# nrf54lilium_network register map
Vendor: Nordic Semiconductor; Series: nrf54; File version: 1
CPU: CM33 r0p4, little endian, MPU, no FPU, 3 interrupt priority bits, 30 interrupts
Registers are 32-bit, read-write, reset 0x0 unless marked. A register's access mark holds for its fields unless they carry their own. Offsets are from the block's base; [hi:lo] are bit positions; {n}, {i} and the like mark numbered series; 'fields as' and 'values as' point back to an identical list.

## RADIO (part 3 of 3) — 2.4 GHz radio 2.4 GHz radio
Base 0x41008000
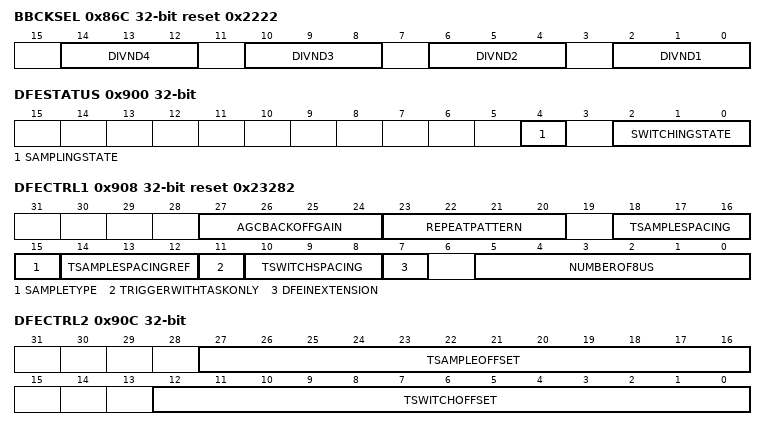
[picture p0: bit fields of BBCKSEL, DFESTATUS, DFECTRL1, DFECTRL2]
0x86C BBCKSEL reset 0x2222 — Clock rates
  [14:12] DIVND4 — Hyper demod clock rate 2
    0=ClkSel_32M (CKSEL_32M); 1=ClkSel_16M (CKSEL_16M); 2=ClkSel_8M (CKSEL_8M); 3=ClkSel_4M (CKSEL_4M); 4=ClkSel_2M (CKSEL_2M); 5=ClkSel_1M (CKSEL_1M); 6=ClkSel_500K (CKSEL_500K); 7=Disabled (CKSEL_OFF)
  [10:8] DIVND3 — Hyper demod clock rate 1
    values as DIVND4
  [6:4] DIVND2 — Standard demod clock rate 2
    values as DIVND4
  [2:0] DIVND1 — Standard demod clock rate 1
    0=ClkSel_32M (CKSEL_32M); 1=ClkSel_16M (CKSEL_16M); 2=ClkSel_8M (CKSEL_8M); 3=ClkSel_4M (CKSEL_4M); 4=ClkSel_2M (CKSEL_2M); 5=ClkSel_1M (CKSEL_1M); 6=ClkSel_500K (CKSEL_500K); 7=ClkSel_Disabled (CKSEL_OFF)
0x900 DFESTATUS ro — DFE status information
  [4] SAMPLINGSTATE — Internal state of sampling state machine
    0=Idle (Sampling state Idle); 1=Sampling state Sampling
  [2:0] SWITCHINGSTATE — Internal state of switching state machine
    0=Idle (Switching state Idle); 1=Offset (Switching state Offset); 2=Guard (Switching state Guard); 3=Ref (Switching state Ref); 4=Switching state Switching; 5=Ending (Switching state Ending)
0x904 DFEMODE — Whether to use Angle-of-Arrival (AOA) or Angle-of-Departure (AOD)
  [1:0] DFEOPMODE — Direction finding operation mode
    0=Disabled (Direction finding mode disabled); 2=AoD (Direction finding mode set to AoD); 3=AoA (Direction finding mode set to AoA)
0x908 DFECTRL1 reset 0x23282 — Various configuration for Direction finding
  [27:24] AGCBACKOFFGAIN — Gain will be lowered by the specified number of gain steps at the start of CTE
  [23:20] REPEATPATTERN — Repeat every antenna pattern N times.
    0=NO_REPEAT (Do not repeat (1 time in total))
  [18:16] TSAMPLESPACING — Interval between samples in the SWITCHING period when CTEINLINECTRLEN is 0
    1=4us; 2=2us; 3=1us; 4=500ns (0.5us); 5=250ns (0.25us); 6=125ns (0.125us)
  [15] SAMPLETYPE — Whether to sample I/Q or magnitude/phase
    0=IQ (Complex samples in I and Q); 1=MagPhase (Complex samples as magnitude and phase)
  [14:12] TSAMPLESPACINGREF — Interval between samples in the REFERENCE period
    0=8us; 1=4us; 2=2us; 3=1us; 4=500ns (0.5us); 5=250ns (0.25us); 6=125ns (0.125us)
  [11] TRIGGERWITHTASKONLY — Trigger AoA/AoD procedure using only task
    1=OnlyTask (Only allow triggering a procedure with TASKS_DFESTART); 0=Multiple (Trigger also with other signals)
  [10:8] TSWITCHSPACING — Interval between every time the antenna is changed in the SWITCHING state
    0=8us; 1=4us; 2=2us; 3=1us; 4=500ns (0.5us); 5=250ns (0.25us)
  [7] DFEINEXTENSION — Add CTE extension and do antenna switching/sampling in this extension
    1=CRC (AoA/AoD procedure triggered at end of CRC); 0=Payload (Antenna switching/sampling is done in the packet payload)
  [5:0] NUMBEROF8US — Length of the AoA/AoD procedure in number of 8 us units
0x90C DFECTRL2 — Start offset for Direction finding
  [27:16] TSAMPLEOFFSET — Signed value offset before starting sampling in number of 16M cycles relative to the beginning of the REFERENCE state - 12 us after switching start
  [12:0] TSWITCHOFFSET — Signed value offset after the end of the CRC before starting switching in number of 16M cycles
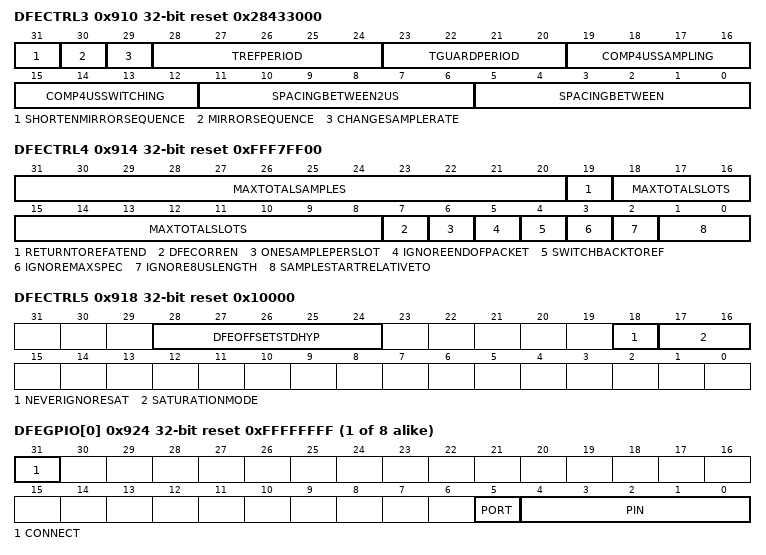
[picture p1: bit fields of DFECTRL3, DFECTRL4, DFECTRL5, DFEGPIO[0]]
0x910 DFECTRL3 reset 0x28433000 — Various hacker/tuning configuration for Direction finding
  [31] SHORTENMIRRORSEQUENCE — Applies only when MIRRORSEQUENCE is set. Selects whether to repeat the end pattern (in both ends) or not
    0=Disable (End patterns are repeated); 1=Enable (End patterns are not repeated)
  [30] MIRRORSEQUENCE — When reaching the last antenna pattern, it repeats that pattern, and then goes back down again.
    0=Disable (Do not mirror the sequence); 1=Enable (Mirror the sequence)
  [29] CHANGESAMPLERATE — Whether to have the ability to have separate sampling rate in the REFERENCE period vs the SWITCHING state
    0=Same (Always use sample spacing given by TSAMPLESPACINGREF); 1=Change (Use TSAMPLESPACINGREF in the REFERENCE period, and TSAMPLESPACING or CTEINLINEAODRXMODExUS in the SWITCHING period)
  [28:24] TREFPERIOD — Length of REFERENCE period in number of microseconds, normally 8
  [23:20] TGUARDPERIOD — Length of GUARD period in number of microseconds, normally 4
  [19:16] COMP4USSAMPLING — Number of 4us periods to subtract from numberOf8us when calculating total number of samples to capture
  [15:12] COMP4USSWITCHING — Number of 4us periods to subtract from numberOf8us when calculating total number of antenna slots switches
  [11:6] SPACINGBETWEEN2US — Same as SPACINGBETWEEN when using CTEINLINECTRL and CTEType is 2 us slots
  [5:0] SPACINGBETWEEN — Signed tuning value for the spacing between the last sample in the reference period and the first sample in the first sample slot
0x914 DFECTRL4 reset 0xFFF7FF00 — Various hacker/tuning configuration for Direction finding
  [31:20] MAXTOTALSAMPLES — Maximum number of samples to capture
  [19] RETURNTOREFATEND — Start position of repeated part of switching pattern sequence
    0=Disable (Return to SWITCHPATTERN[2] after reaching the end of the switching pattern sequence); 1=Enable (Return to SWITCHPATTERN[1] after reaching the end of the switching pattern sequence)
  [18:8] MAXTOTALSLOTS — Maximum number of antenna slots
  [7] DFECORREN — Enable correlator before Direction Finding samples
    0=Disable correlator; 1=Enable correlator
  [6] ONESAMPLEPERSLOT — TSAMPLESPACING is ignored for the samples taken in the SWITCHING state TSAMPLESPACINGREF is still used for the first samples (REFERENCE period)
  [5] IGNOREENDOFPACKET — Ignore that the UTxRxChain says that the packet has been received Continue running if more time to run
    0=Do not ignore the end of packet; 1=Ignore the end of packet
  [4] SWITCHBACKTOREF — Insert reference antenna(SWITCHPATTERN[1]) between antenna switches, from SWITCHPATTERN[2] onwards
    0=Disable (Do not insert reference antenna between switches); 1=Enable (Insert reference antenna between switches)
  [3] IGNOREMAXSPEC — Ignore the maximum number of samples and antenna slots specified with MAXTOTALSAMPLES and MAXTOTALSLOTS
    0=DoNotIgnore (Use the max specs); 1=Ignore the max specs
  [2] IGNORE8USLENGTH — Ignore the length specification in numberOf8us
    0=DoNotIgnore (Use the length specification); 1=Ignore the length specification
  [1:0] SAMPLESTARTRELATIVETO — Start point of TSAMPLEOFFSET sampling relative to which part in the switching state machine
    0=Reference (At the start of the reference antenna period); 1=Switching (At the start of antenna switching after the reference antenna period); 2=Trigger (When it is triggered Either TASKS_DFESTART, address match or AoA/AoD procedure trigger source); 3=Guard (At the start of the GUARD period)
0x918 DFECTRL5 reset 0x10000 — Various hacker/tuning configuration for Direction finding
  [28:24] DFEOFFSETSTDHYP — Tuning of the timing difference between the hypermode demodulator and the standard demodulator for the DFE start event, in 62.5 ns units
  [18] NEVERIGNORESAT — Selects whether saturation (being reported from the radio front-end) should be ignored in the beginning of the slot or not
    0=IGNORE (Saturation being indicated from the front-end is ignored if it happens in the first 40 percent of the sample spacing after a sample was saved to RAM); 1=NEVERIGNORE (Saturation is always reported in RAM if detected by the frontend)
  [17:16] SATURATIONMODE — Set how input saturation will be present in the captured samples
    0=OFF (No saturation is presented); 1=SETMINVAL (Saturation is marked by setting both I and Q to -32768 (or mag/phase if SAMPLETYPE is 1)); 2=SATURATIONBIT (Bit 15 of both the I and Q values indicates saturation. I and Q are hence only 15 bit values)
0x91C SWITCHPATTERN ro — GPIO patterns to be used for each antenna
  [7:0] SWITCHPATTERN — Fill array of GPIO patterns for antenna control
0x920 CLEARPATTERN wo — Clear the GPIO pattern array for antenna control
  [0] CLEARPATTERN — Clear the GPIO pattern array for antenna control Behaves as a task register, but does not have PPI nor IRQ
{0x924+4i} DFEGPIO[{i}] (i=0..7) reset 0xFFFFFFFF — Description collection: Pin select for DFE pin n
  [31] CONNECT — Connection
    1=Disconnected; 0=Connected
  [5] PORT — Port number
  [4:0] PIN — Pin number
0x944 TASK_TRIG_START_DFE wo — Unspecified
  [0] TASK_TRIG_START_DFE
0x948 TASK_TRIG_STOP_DFE wo — Unspecified
  [0] TASK_TRIG_STOP_DFE
0x94C ENABLE_DFE — Unspecified
  [0] ENABLE_DFE
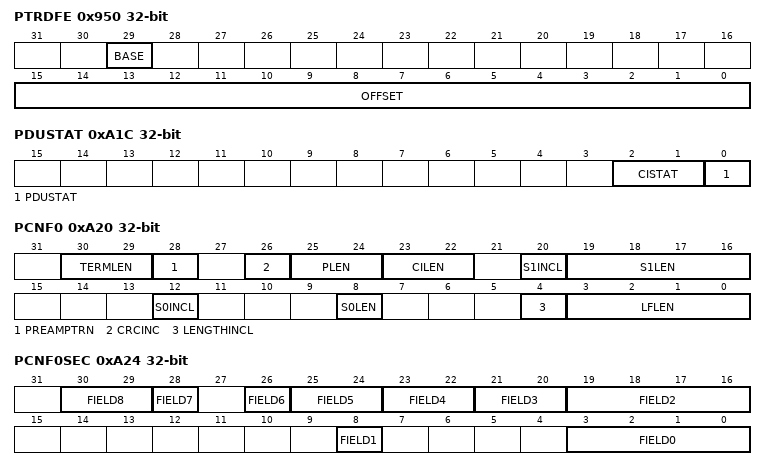
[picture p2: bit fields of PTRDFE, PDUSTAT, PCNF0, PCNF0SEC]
0x950 PTRDFE — Data pointer
  [29] BASE, [15:0] OFFSET
0x954 AMOUNTDFE ro — Number of samples transferred in the last transaction
  [15:0] AMOUNTDFE
0x958 MAXCNTDFE reset 0xFFFFFFFF — Maximum number of buffer words to transfer
  [15:0] MAXCNTDFE
0xA00 TASK_CNTSTART wo — Unspecified
  [0] TASK_CNTSTART
0xA04 TASK_CNTSTOP wo — Unspecified
  [0] TASK_CNTSTOP
0xA08 TASK_CNTCLEAR wo — Unspecified
  [0] TASK_CNTCLEAR
0xA0C CRCSTATUS ro
  [0] CRCSTATUS — CRC status of packet received
    0=CRCError (Packet received with CRC error); 1=CRCOk (Packet received with CRC ok)
0xA10 RXMATCH ro — Received address
  [2:0] RXMATCH
0xA14 RXCRC ro — CRC field of previously received packet
  [23:0] RXCRC
0xA18 DAI ro — Device address match index
  [2:0] DAI
0xA1C PDUSTAT ro — Payload status
  [2:1] CISTAT — Status on what rate packet is received with in Long Range
    0=LR125kbit (Frame is received at 125 kbps); 1=LR500kbit (Frame is received at 500 kbps)
  [0] PDUSTAT — Status on payload length vs. PCNF1.MAXLEN
    0=LessThan (Payload less than PCNF1.MAXLEN); 1=GreaterThan (Payload greater than PCNF1.MAXLEN)
0xA20 PCNF0 — Packet configuration register 0
  [30:29] TERMLEN — Length of TERM field in Long Range operation
  [28] PREAMPTRN — Preamble pattern
  [26] CRCINC — Indicates if LENGTH field contains CRC or not
    0=Exclude (LENGTH does not contain CRC); 1=Include (LENGTH includes CRC)
  [25:24] PLEN — Length of preamble on air. Decision point: TASKS_START task
    0=8-bit preamble; 1=16-bit preamble; 2=32-bit zero preamble - used for IEEE 802.15.4; 3=LongRange (Preamble - used for BLE long range)
  [23:22] CILEN — Length of code indicator - long range
  [20] S1INCL — Include or exclude S1 field in RAM
    0=Automatic (Include S1 field in RAM only if S1LEN > 0); 1=Include (Always include S1 field in RAM independent of S1LEN)
  [19:16] S1LEN — Length on air of S1 field in number of bits.
  [12] S0INCL — Include or exclude S0 field in RAM
    0=Automatic (Include S0 field only if S0LEN > 0)
  [8] S0LEN — Length on air of S0 field in number of bytes.
  [4] LENGTHINCL — Include or exclude LENGTH field in RAM
    0=Automatic (Include LENGTH field in RAM only if LFLEN > 0)
  [3:0] LFLEN — Length on air of LENGTH field in number of bits.
0xA24 PCNF0SEC — Unspecified
  [30:29] FIELD8, [28] FIELD7, [26] FIELD6, [25:24] FIELD5, [23:22] FIELD4, [21:20] FIELD3, [19:16] FIELD2, [8] FIELD1, [3:0] FIELD0
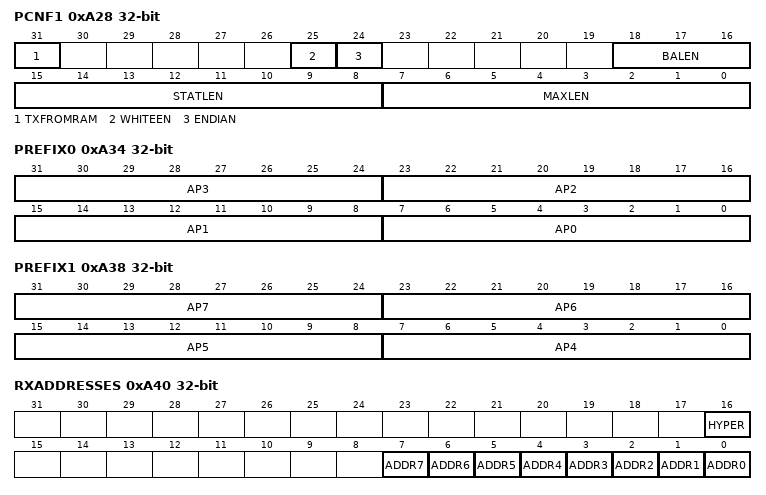
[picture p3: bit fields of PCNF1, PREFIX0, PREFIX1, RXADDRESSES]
0xA28 PCNF1 — Packet configuration register 1
  [31] TXFROMRAM — Used to bypass PREAMBLE, ADDRESS, S0, LENGTH, S1 field and go straight to PAYLOAD state
    0=Disabled; 1=Bypass
  [25] WHITEEN — Enable or disable packet whitening
    0=Disabled; 1=Enabled
  [24] ENDIAN — On-air endianness of packet, this applies to the S0, LENGTH, S1, and the PAYLOAD fields.
    0=Little (Least significant bit on air first); 1=Big (Most significant bit on air first)
  [18:16] BALEN — Base address length in number of bytes
  [15:8] STATLEN — Static length in number of bytes
  [7:0] MAXLEN — Maximum length of packet payload. If the packet payload is larger than MAXLEN, the radio will truncate the payload to MAXLEN.
0xA2C BASE0 — Base address 0
0xA30 BASE1 — Base address 1
0xA34 PREFIX0 — Prefixes bytes for logical addresses 0-3
  [8n+7:8n] AP{n} (n=0..3) — Address prefix {n}.
0xA38 PREFIX1 — Prefixes bytes for logical addresses 4-7
  [8n-25:8n-32] AP{n} (n=4..7) — Address prefix {n}.
0xA3C TXADDRESS — Transmit address select
  [2:0] TXADDRESS
0xA40 RXADDRESSES — Receive address select
  [16] HYPER — Hypermode settings
    0=B0 (Use hypermode for address ADDR0 (base address 0 RADIO.BASE0)); 1=B1 (From all of the enabled addresses among ADDR1 through ADDR7, the address ADDRn with the highest index number 'n' will use hypermode (base address 1 RADIO.BASE1))
  [n] ADDR{n} (n=0..7) — Enable or disable reception on logical address {n}.
    0=Disabled; 1=Enabled
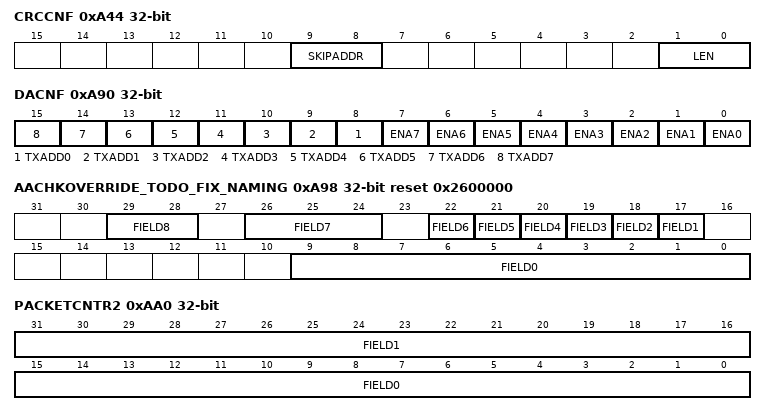
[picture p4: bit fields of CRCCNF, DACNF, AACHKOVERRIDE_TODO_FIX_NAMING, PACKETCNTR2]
0xA44 CRCCNF — CRC configuration
  [9:8] SKIPADDR — Include or exclude packet address field out of CRC calculation.
    0=Include (CRC calculation includes address field); 1=Skip (CRC calculation does not include address field. The CRC calculation will start at the first byte after the address.); 2=Ieee802154 (CRC calculation as per 802.15.4 standard. Starting at first byte after length field.)
  [1:0] LEN — CRC length in number of bytes.
    0=Disabled (CRC length is zero and CRC calculation is disabled); 1=One (CRC length is one byte and CRC calculation is enabled); 2=Two (CRC length is two bytes and CRC calculation is enabled); 3=Three (CRC length is three bytes and CRC calculation is enabled)
0xA48 CRCPOLY — CRC polynomial
  [23:0] CRCPOLY
0xA4C CRCINIT — CRC initial value
  [23:0] CRCINIT
{0xA50+4i} DAB[{i}] (i=0..7) — Description collection: Device address base segment n
  [31:0] DAB — Device address base segment n
{0xA70+4i} DAP[{i}] (i=0..7) — Description collection: Device address prefix n
  [15:0] DAP — Device address prefix n
0xA90 DACNF — Device address match configuration
  [n+8] TXADD{n} (n=0..7) — TxAdd for device address {n}
  [n] ENA{n} (n=0..7) — Enable or disable device address matching using device address {n}
    0=Disabled; 1=Enabled
0xA94 BCC — Bit counter compare
0xA98 AACHKOVERRIDE_TODO_FIX_NAMING reset 0x2600000 — Unspecified
  [29:28] FIELD8, [26:24] FIELD7, [n+16] FIELD{n} (n=1..6), [9:0] FIELD0
0xA9C PACKETCNTR1 ro — Unspecified
  [15:0] FIELD0
0xAA0 PACKETCNTR2 ro — Unspecified
  [31:16] FIELD1, [15:0] FIELD0
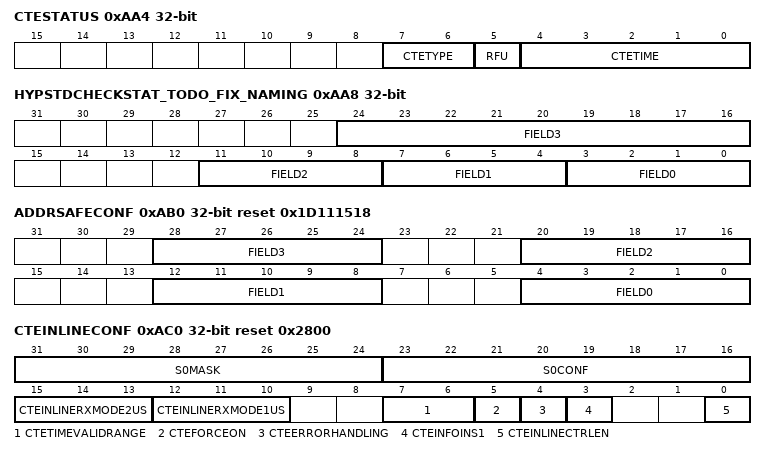
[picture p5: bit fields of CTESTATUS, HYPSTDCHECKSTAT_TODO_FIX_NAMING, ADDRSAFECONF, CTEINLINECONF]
0xAA4 CTESTATUS ro — CTEInfo parsed from received packet
  [7:6] CTETYPE — CTEType parsed from packet
  [5] RFU — RFU parsed from packet
  [4:0] CTETIME — CTETime parsed from packet
0xAA8 HYPSTDCHECKSTAT_TODO_FIX_NAMING ro — Unspecified
  [24:16] FIELD3, [11:8] FIELD2, [7:4] FIELD1, [3:0] FIELD0
0xAAC HYPSTDAADIFFVEC_TODO_FIX_NAMING ro — Unspecified
  [15:0] FIELD0
0xAB0 ADDRSAFECONF reset 0x1D111518 — Unspecified
  [8n+4:8n] FIELD{n} (n=0..3)
0xAB4 MHRMATCHCONF — Search pattern configuration
0xAB8 MHRMATCHMASK — Pattern mask
0xABC SFD reset 0xA7 — IEEE 802.15.4 start of frame delimiter
  [7:0] SFD
0xAC0 CTEINLINECONF reset 0x2800 — Configuration for CTE inline mode
  [31:24] S0MASK — S0 bit mask to set which bit to match
  [23:16] S0CONF — S0 bit pattern to match
  [15:13] CTEINLINERXMODE2US — Spacing between samples for the samples in the SWITCHING period when CTEINLINEMODE is set
    values as DFECTRL1.TSAMPLESPACINGREF
  [12:10] CTEINLINERXMODE1US — Spacing between samples for the samples in the SWITCHING period when CTEINLINEMODE is set
    values as DFECTRL1.TSAMPLESPACINGREF
  [7:6] CTETIMEVALIDRANGE — Max range of CTETime
    0=20 in 8us unit (default) Set to 20 if parsed CTETime is larger han 20; 1=31 in 8us unit; 2=63 in 8us unit
  [5] CTEFORCEON — CTE is continuously output after CRC and only stopped by triggering TASKS_STOP. This is typically used together with the DFEEND to STOP short. AoA/AoD procedure duration is still controlled by DFECTRL1.NUMBEROF8S / CTETIME
    1=Yes (CTE is continuously transmitted after CRC until TASKS_STOP); 0=No (CTE duration is automatically determined by DFECTRL1.NUMBEROF8US / CTETIME (only correct for 1Mbps and 2Mbps modes))
  [4] CTEERRORHANDLING — Sampling/switching if CRC is not OK
    1=Yes (Sampling and antenna switching also when CRC is not OK); 0=No (No sampling and antenna switching when CRC is not OK)
  [3] CTEINFOINS1 — CTEInfo is S1 byte or not
    1=InS1 (CTEInfo is in S1 byte (data PDU)); 0=NotInS1 (CTEInfo is NOT in S1 byte (advertising PDU))
  [0] CTEINLINECTRLEN — Enable parsing of CTEInfo from received packet in BLE modes
    1=Enabled (Parsing of CTEInfo is enabled); 0=Disabled (Parsing of CTEInfo is disabled)
0xAC4 TASK_TRIG_START_CHAIN wo — Unspecified
  [0] TASK_TRIG_START_CHAIN
0xAC8 TASK_TRIG_STOP_CHAIN wo — Unspecified
  [0] TASK_TRIG_STOP_CHAIN
0xACC ENABLE_CHAIN — Unspecified
  [0] ENABLE_CHAIN
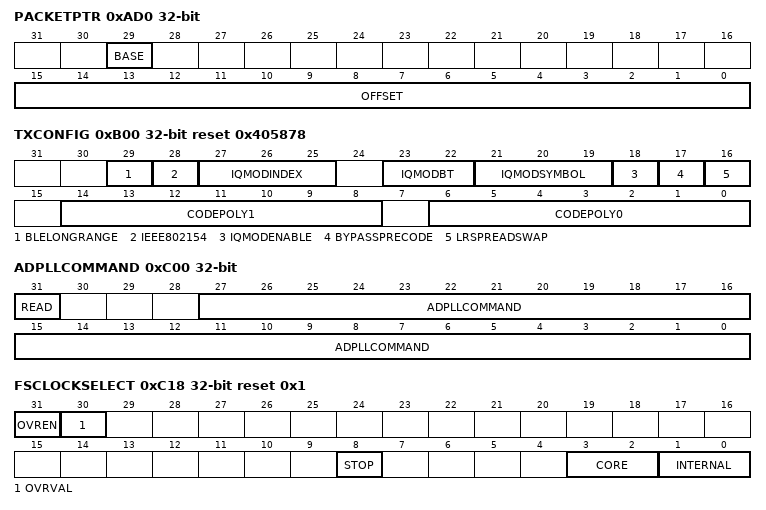
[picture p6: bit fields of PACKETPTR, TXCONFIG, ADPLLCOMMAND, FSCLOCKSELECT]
0xAD0 PACKETPTR — Packet pointer
  [29] BASE, [15:0] OFFSET
0xAD4 AMOUNT_CHAIN ro — Unspecified
  [0] AMOUNT_CHAIN
0xAD8 MAXCNT_CHAIN reset 0xFFFFFFFF — Unspecified
  [0] MAXCNT_CHAIN
0xB00 TXCONFIG reset 0x405878 — Tx configuration-
  [29] BLELONGRANGE — Enable long range mode (Do not enable both IEEE802154 and BLELONGRANGE)
    0=Disable (BLELONGRANGE_NO); 1=Enable (BLELONGRANGE_YES)
  [28] IEEE802154 — Enable 15.4 mode (Do not enable both IEEE802154 and BLELONGRANGE)
    0=Disable (IEEE802154_NO); 1=Enable (IEEE802154_YES)
  [27:25] IQMODINDEX — IQMOD modulation index.
    0=ModIndex_0h25; 1=ModIndex_0h32; 2=ModIndex_0h5; 3=ModIndex_1h0; 4=ModIndex_2h0
  [23:22] IQMODBT — IQMOD GFSK bandwidth.
    0=0bt55; 1=0bt60
  [21:19] IQMODSYMBOL — IQMOD additional symbol mapping not set by MODE.
  [18] IQMODENABLE — Enable IQ modulator.
  [17] BYPASSPRECODE — Bypass MSK precoding.
  [16] LRSPREADSWAP — Swap pattern mapping. Default 0, 0 is mapped to a 0011 sequence, 1 is mapped to a 1100 sequence. If swap bit is set, 1 is mapped to a 0011 sequence, 0 is mapped to a 1100 sequence.
  [14:8] CODEPOLY1 — Code polynomial 1
  [6:0] CODEPOLY0 — Code polynomial 0
0xC00 ADPLLCOMMAND — Send or receive command directly to the AdPll digital island. Only write to this register when FSASYNCBUSBUSY returns 0
  [31] READ — When 1, a read transaction is initiated. When the event COMPLETETRANS is set, read back this register
  [27:0] ADPLLCOMMAND — Controls the asynch interface, bits[27:16] are address, bits [15:0] are command/data field
0xC04 FSFREQFINETUNE — For finetuning the frequency
  [12:0] FSFREQFINETUNE — 2-complement number for fine-tuning the frequency in steps of 488.28 Hz
0xC08 DEVIATION reset 0x55 — Frequency deviation for modulation
  [9:0] DEVIATION
0xC0C MODRATE reset 0x2 — Select modulation rate
  [2:0] MODRATE
    0=250 kbps; 1=500 kbps; 2=1M (1 Mbps); 3=2M (2 Mbps); 4=4M (4 Mbps)
0xC10 MODFILTERING reset 0x2 — Select gaussian filtering mode
  [1:0] MODFILTERING
    0=None (No filtering); 1=0bt55 (Gfsk Bt=0.55); 2=0bt60 (Gfsk Bt=0.60)
0xC14 CUSTOMMODULATION — Enable reading from memory and passing data over to AdPll
  [0] ENABLE
0xC18 FSCLOCKSELECT reset 0x1 — Set the clock source for the AdPll digital island
  [31] OVREN — Override enable for setting the clock switch. If 0, fsStart decides which clock to use. If 1, FSCLOCKSELECT.OVRVAL selects which clock to use
  [30] OVRVAL — Used instead of 'fsStart' if FSCLOCKSELECT.OVREN is set
  [8] STOP — Force-stopping the clock internally in the AdPll island
  [3:2] CORE — Set the clock source for the AdPll digital island when fsStart is low
  [1:0] INTERNAL — Set the clock source for the AdPll digital island when fsStart is high
0xC1C FSUNITRIGCALVAL ro — Read the calibrated value for the universal trigger
  [4:0] FSUNITRIGCALVAL
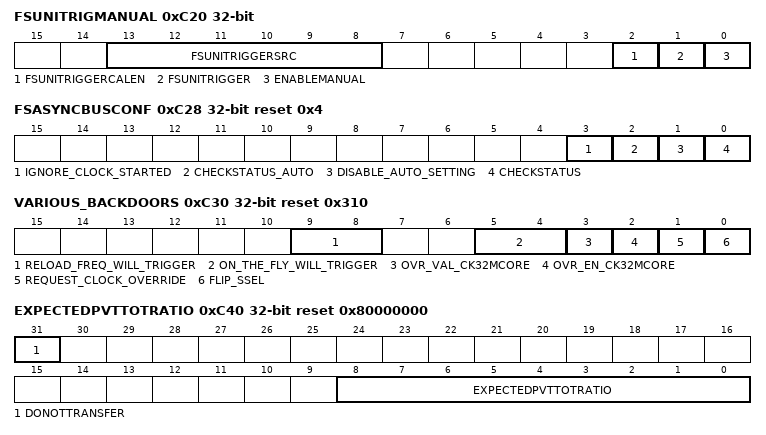
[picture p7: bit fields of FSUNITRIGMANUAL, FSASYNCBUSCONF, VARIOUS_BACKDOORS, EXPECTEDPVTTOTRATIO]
0xC20 FSUNITRIGMANUAL — Manual control of the uni trigger signals. Note that fsUniTriggerCalWord is controlled by writing to the separate register FSUNITRIGCALVAL
  [13:8] FSUNITRIGGERSRC — The fsUniTriggerCalSrc signal when using manual control
  [2] FSUNITRIGGERCALEN — The fsUniTriggerCalEn signal when using manual control
  [1] FSUNITRIGGER — The fsUniTrigger signal when using manual control
  [0] ENABLEMANUAL — Enable manual control
0xC24 FSUNITRIGCALOUT ro — Read the signal directly from fsUniTriggerCalOut
  [1:0] FSUNITRIGCALOUT — Read the raw fsUniTriggerCalOut value
0xC28 FSASYNCBUSCONF reset 0x4 — Some special settings for the asynchronous bus configuration
  [3] IGNORE_CLOCK_STARTED — The bus scheduler will not wait for AdPll to say clockStarted
  [2] CHECKSTATUS_AUTO — When 1, check the first transaction during sending auto. If errorenous stop the state machine
  [1] DISABLE_AUTO_SETTING — Do not send settings at the beginning to AdPll
  [0] CHECKSTATUS — When 1, every transaction uses 8 x 32 MHz clock cycles instead of 4 x 32 MHz clock cycles. Confirmation is received whether the transaction was actually received by AdPll.
0xC2C FSASYNCBUSBUSY ro reset 0x1 — Status bit indicating whether the bus is currently busy or not
  [0] FSASYNCBUSBUSY — Whether the bus is currently busy or not
0xC30 VARIOUS_BACKDOORS reset 0x310 — This value is written to the AdPll when powering up the digital island
  [9:8] RELOAD_FREQ_WILL_TRIGGER — 0: no relock, 1: first gear of TRK, 2: back to ACQ, 3: back to full lock
  [5:4] ON_THE_FLY_WILL_TRIGGER — 0: no relock, 1: first gear of TRK, 2: back to ACQ, 3: back to full lock
  [3] OVR_VAL_CK32MCORE — Whether ck32MCore is active or not when OVR_EN_CK32MCORE is set. See also description of OVR_EN_CK32MCORE
  [2] OVR_EN_CK32MCORE — Make it possible to manually control whether ck32MCore is sent to the AdPll digital island. Needed to test complete clock silence in the AdPll island. It can also be used to enable the clock activity on the clock net even when the clock is not selected.
  [1] REQUEST_CLOCK_OVERRIDE — In normal operation we request clock when pwrupFsLdoDig0 is set. By setting this to 1, we will request clock even when pwrupFsLdoDig0. This may be useful for current measurements of FS_DIG
  [0] FLIP_SSEL — If 0, we flip the interpretation of the sSel signal (to work around a bug if we have managed to flip it somewhere in the design process)
0xC40 EXPECTEDPVTTOTRATIO reset 0x80000000 — This value is written to the AdPll when powering up the digital island
  [31] DONOTTRANSFER — When 1, we do not transfer this word to AdPll at power up
  [8:0] EXPECTEDPVTTOTRATIO — The ratio between PVT and the total cap ratio. Used for Estkmod, Estkdtc and TdcReadout
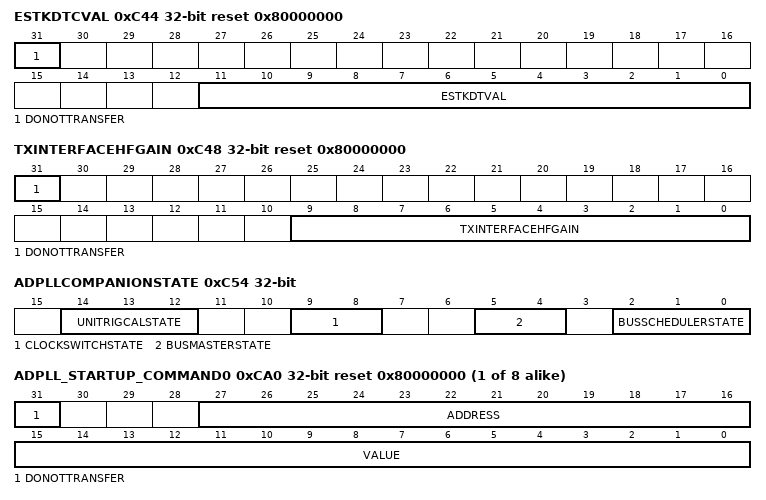
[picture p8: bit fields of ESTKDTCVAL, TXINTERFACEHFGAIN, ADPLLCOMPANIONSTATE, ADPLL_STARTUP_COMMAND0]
0xC44 ESTKDTCVAL reset 0x80000000 — This value is written to the AdPll when powering up the digital island
  [31] DONOTTRANSFER — When 1, we do not transfer this word to AdPll at power up
  [11:0] ESTKDTVAL — The estimated kDTV value in typical
0xC48 TXINTERFACEHFGAIN reset 0x80000000 — This value is written to the AdPll when powering up the digital island
  [31] DONOTTRANSFER — When 1, we do not transfer this word to AdPll at power up
  [9:0] TXINTERFACEHFGAIN — The gain for the HF path
0xC4C TRACING — Enable tracing from AdPll
  [0] ENABLE
0xC50 IFFREQ — Select between two different IF frequencies
  [0] HIGHIF
    0=1 MHz IF; 1=2 MHz IF
0xC54 ADPLLCOMPANIONSTATE ro — State in the AdPllCompanion state machines
  [14:12] UNITRIGCALSTATE — The state of the universal trigger calibration routine
  [9:8] CLOCKSWITCHSTATE — The state of the clock switching state machine
  [5:4] BUSMASTERSTATE — The state of the async bus master
  [2:0] BUSSCHEDULERSTATE — The state of the state machine which sends commands automatically at startup
0xC70 RELOADFREQ — Non-official task: AdPll will reread the frequency input signal
  [0] TRIGGER
0xC74 UNITRIGCALSTART — Non-official task: Start automatic universal trigger calibration
  [0] TRIGGER
0xC78 FSSENDSETTINGS — Non-official task: Send the auto-settings to AdPll again. This also happens at every startup
  [0] TRIGGER
0xC80 UNITRIGCALDONE — Non-official event: Start automatic universal trigger calibration
  [0] VAL
0xC84 REJECTEDTRANS — Non-official event: The command written to AdPll was rejected because of an ongoing transaction
  [0] VAL
0xC88 COMPLETETRANS — Non-official event: Completed a transaction to AdPll successfully ((only when CHECKSTATUS is set)
  [0] VAL
0xC8C FAILEDTRANS — Non-official event: Did not successfully complete a transaction to AdPll. (only when CHECKSTATUS is set)
  [0] VAL
{0xCA0+4i} ADPLL_STARTUP_COMMAND{i} reset 0x80000000 (i=0..7) — This value is written to the AdPll when powering up the digital island
  [31] DONOTTRANSFER — When 1, we do not transfer this word to AdPll at power up
  [27:16] ADDRESS — The address of the digital island to write to
  [15:0] VALUE — The value to be written the register in the digital island
0xCD0 ADPLLCOMPANION_INTEN — Unspecified
  [3:0] ADPLLCOMPANION_INTEN
0xCD4 ADPLLCOMPANION_INTENSET write-1-sets — Unspecified
  [3:0] ADPLLCOMPANION_INTENSET
0xCD8 ADPLLCOMPANION_INTENCLR write-1-clears — Unspecified
  [3:0] ADPLLCOMPANION_INTENCLR
0xCDC ADPLLCOMPANION_INTPEND ro — Unspecified
  [3:0] ADPLLCOMPANION_INTPEND
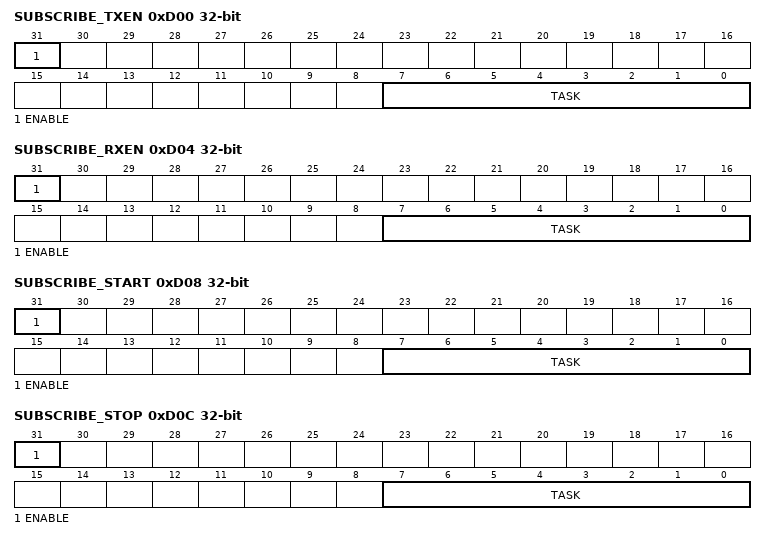
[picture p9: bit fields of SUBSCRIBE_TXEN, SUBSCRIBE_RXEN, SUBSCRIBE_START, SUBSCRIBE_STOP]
0xD00 SUBSCRIBE_TXEN — Unspecified
  [31] ENABLE, [7:0] TASK
0xD04 SUBSCRIBE_RXEN — Unspecified
  [31] ENABLE, [7:0] TASK
0xD08 SUBSCRIBE_START — Unspecified
  [31] ENABLE, [7:0] TASK
0xD0C SUBSCRIBE_STOP — Unspecified
  [31] ENABLE, [7:0] TASK
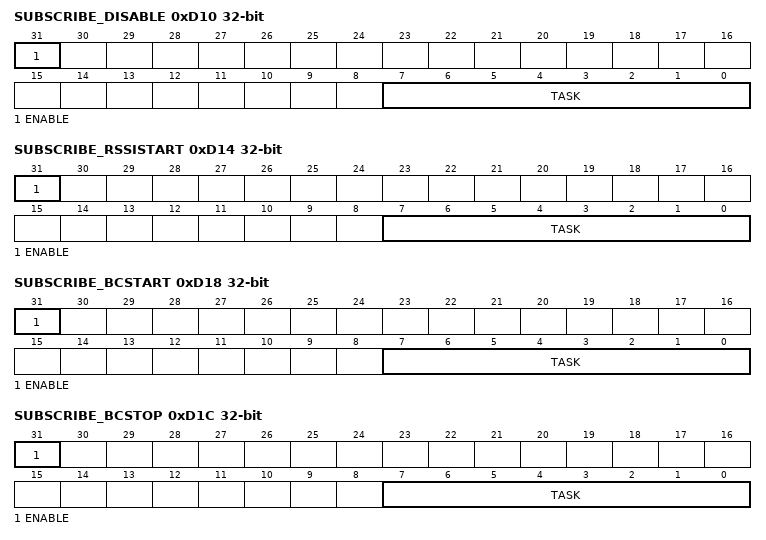
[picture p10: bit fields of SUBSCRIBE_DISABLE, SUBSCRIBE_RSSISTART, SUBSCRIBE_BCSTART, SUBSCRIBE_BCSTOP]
0xD10 SUBSCRIBE_DISABLE — Unspecified
  [31] ENABLE, [7:0] TASK
0xD14 SUBSCRIBE_RSSISTART — Unspecified
  [31] ENABLE, [7:0] TASK
0xD18 SUBSCRIBE_BCSTART — Unspecified
  [31] ENABLE, [7:0] TASK
0xD1C SUBSCRIBE_BCSTOP — Unspecified
  [31] ENABLE, [7:0] TASK
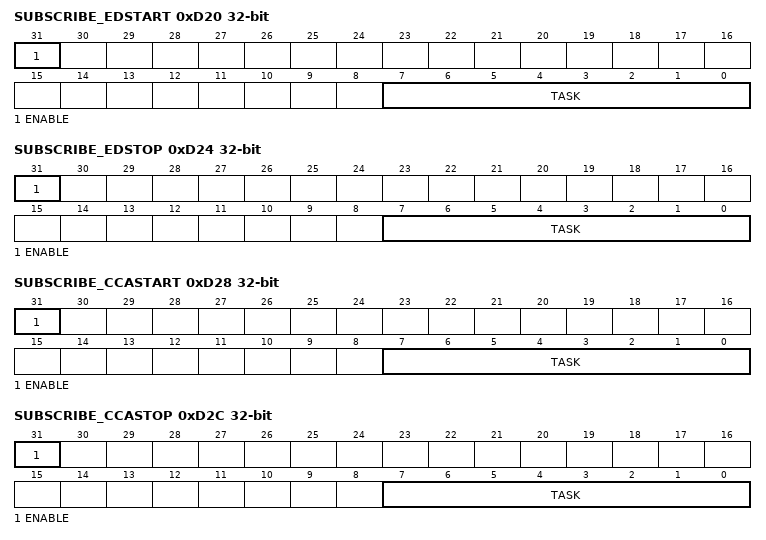
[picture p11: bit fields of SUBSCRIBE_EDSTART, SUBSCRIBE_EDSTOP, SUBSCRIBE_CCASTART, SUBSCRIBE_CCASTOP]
0xD20 SUBSCRIBE_EDSTART — Unspecified
  [31] ENABLE, [7:0] TASK
0xD24 SUBSCRIBE_EDSTOP — Unspecified
  [31] ENABLE, [7:0] TASK
0xD28 SUBSCRIBE_CCASTART — Unspecified
  [31] ENABLE, [7:0] TASK
0xD2C SUBSCRIBE_CCASTOP — Unspecified
  [31] ENABLE, [7:0] TASK
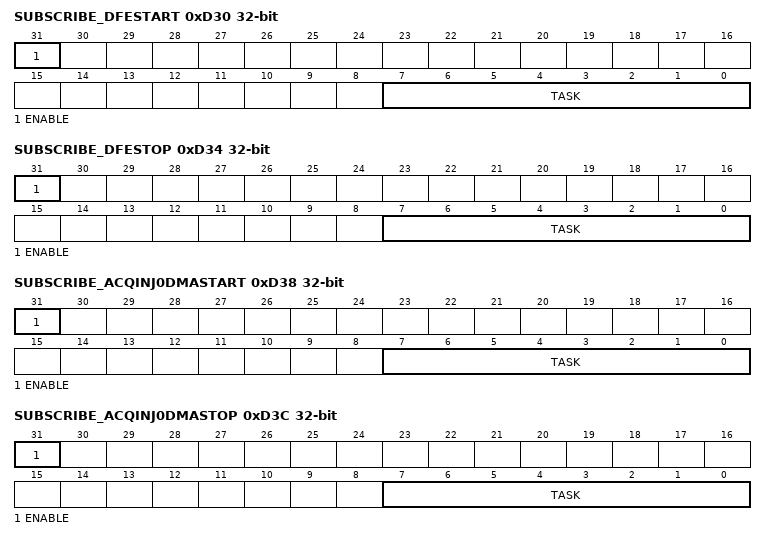
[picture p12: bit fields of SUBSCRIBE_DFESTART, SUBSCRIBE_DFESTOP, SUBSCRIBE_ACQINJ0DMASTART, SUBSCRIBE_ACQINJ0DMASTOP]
0xD30 SUBSCRIBE_DFESTART — Unspecified
  [31] ENABLE, [7:0] TASK
0xD34 SUBSCRIBE_DFESTOP — Unspecified
  [31] ENABLE, [7:0] TASK
0xD38 SUBSCRIBE_ACQINJ0DMASTART — Unspecified
  [31] ENABLE, [7:0] TASK
0xD3C SUBSCRIBE_ACQINJ0DMASTOP — Unspecified
  [31] ENABLE, [7:0] TASK
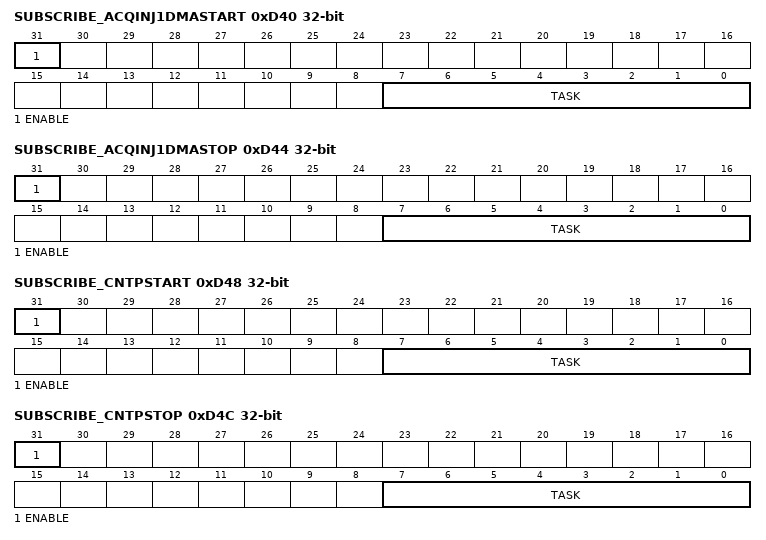
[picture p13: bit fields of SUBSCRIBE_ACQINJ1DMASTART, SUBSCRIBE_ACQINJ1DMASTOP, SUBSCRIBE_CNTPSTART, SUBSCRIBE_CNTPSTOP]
0xD40 SUBSCRIBE_ACQINJ1DMASTART — Unspecified
  [31] ENABLE, [7:0] TASK
0xD44 SUBSCRIBE_ACQINJ1DMASTOP — Unspecified
  [31] ENABLE, [7:0] TASK
0xD48 SUBSCRIBE_CNTPSTART — Unspecified
  [31] ENABLE, [7:0] TASK
0xD4C SUBSCRIBE_CNTPSTOP — Unspecified
  [31] ENABLE, [7:0] TASK
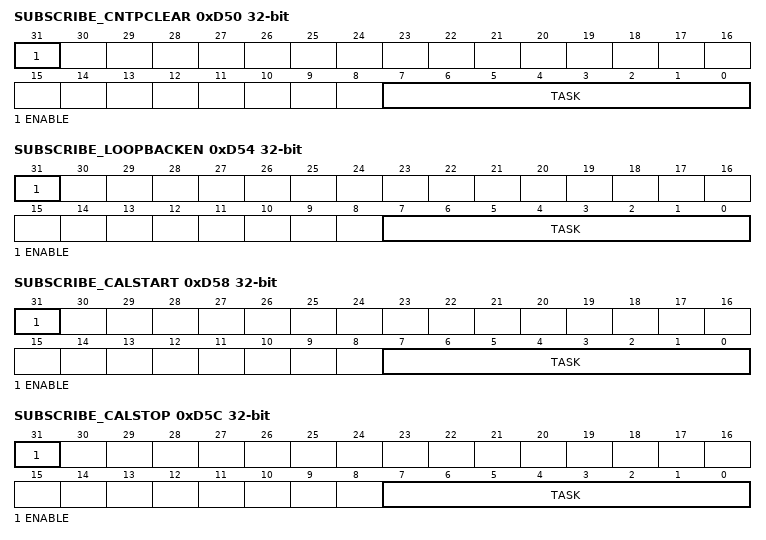
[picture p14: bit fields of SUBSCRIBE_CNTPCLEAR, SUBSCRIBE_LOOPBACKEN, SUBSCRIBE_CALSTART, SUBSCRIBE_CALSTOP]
0xD50 SUBSCRIBE_CNTPCLEAR — Unspecified
  [31] ENABLE, [7:0] TASK
0xD54 SUBSCRIBE_LOOPBACKEN — Unspecified
  [31] ENABLE, [7:0] TASK
0xD58 SUBSCRIBE_CALSTART — Unspecified
  [31] ENABLE, [7:0] TASK
0xD5C SUBSCRIBE_CALSTOP — Unspecified
  [31] ENABLE, [7:0] TASK
0xD60 SUBSCRIBE_PATESTSTART — Unspecified
  [31] ENABLE, [7:0] TASK
0xD64 SUBSCRIBE_PATESTSTOP — Unspecified
  [31] ENABLE, [7:0] TASK
0xD68 SUBSCRIBE_CHNOINCR — Unspecified
  [31] ENABLE, [7:0] TASK
0xD6C SUBSCRIBE_DMASTART — Unspecified
  [31] ENABLE, [7:0] TASK
0xD70 SUBSCRIBE_DMASTOP — Unspecified
  [31] ENABLE, [7:0] TASK
0xD74 SUBSCRIBE_DFEDMASTART — Unspecified
  [31] ENABLE, [7:0] TASK
0xD78 SUBSCRIBE_DFEDMASTOP — Unspecified
  [31] ENABLE, [7:0] TASK
0xD7C SUBSCRIBE_RESERVED31 — Unspecified
  [31] ENABLE, [7:0] TASK
0xD80 SUBSCRIBE_GETNEXTDETECT — Unspecified
  [31] ENABLE, [7:0] TASK
0xD84 SUBSCRIBE_CLEARDETECTFIFO — Unspecified
  [31] ENABLE, [7:0] TASK
0xD88 SUBSCRIBE_RESETDEMODCTRL — Unspecified
  [31] ENABLE, [7:0] TASK
0xD8C SUBSCRIBE_DEMODCTRLSTARTTIMER — Unspecified
  [31] ENABLE, [7:0] TASK
0xD90 SUBSCRIBE_DEMODCTRLSTOPTIMER — Unspecified
  [31] ENABLE, [7:0] TASK
{0xD94+4i} SUBSCRIBE_DEMODCTRLCONDEN{i} (i=0..2) — Unspecified
  [31] ENABLE, [7:0] TASK
0xE00 PUBLISH_READY — Unspecified
  [31] ENABLE, [7:0] EVENT
0xE04 PUBLISH_TXREADY — Unspecified
  [31] ENABLE, [7:0] EVENT
0xE08 PUBLISH_RXREADY — Unspecified
  [31] ENABLE, [7:0] EVENT
0xE0C PUBLISH_ADDRESS — Unspecified
  [31] ENABLE, [7:0] EVENT
0xE10 PUBLISH_FRAMESTART — Unspecified
  [31] ENABLE, [7:0] EVENT
0xE14 PUBLISH_PAYLOAD — Unspecified
  [31] ENABLE, [7:0] EVENT
0xE18 PUBLISH_END — Unspecified
  [31] ENABLE, [7:0] EVENT
0xE1C PUBLISH_PHYEND — Unspecified
  [31] ENABLE, [7:0] EVENT
0xE20 PUBLISH_DISABLED — Unspecified
  [31] ENABLE, [7:0] EVENT
0xE24 PUBLISH_DEVMATCH — Unspecified
  [31] ENABLE, [7:0] EVENT
0xE28 PUBLISH_DEVMISS — Unspecified
  [31] ENABLE, [7:0] EVENT
0xE2C PUBLISH_CRCOK — Unspecified
  [31] ENABLE, [7:0] EVENT
0xE30 PUBLISH_CRCERROR — Unspecified
  [31] ENABLE, [7:0] EVENT
0xE34 PUBLISH_RESERVED13 — Unspecified
  [31] ENABLE, [7:0] EVENT
0xE38 PUBLISH_BCMATCH — Unspecified
  [31] ENABLE, [7:0] EVENT
0xE3C PUBLISH_EDEND — Unspecified
  [31] ENABLE, [7:0] EVENT
0xE40 PUBLISH_EDSTOPPED — Unspecified
  [31] ENABLE, [7:0] EVENT
0xE44 PUBLISH_CCAIDLE — Unspecified
  [31] ENABLE, [7:0] EVENT
0xE48 PUBLISH_CCABUSY — Unspecified
  [31] ENABLE, [7:0] EVENT
0xE4C PUBLISH_CCASTOPPED — Unspecified
  [31] ENABLE, [7:0] EVENT
0xE50 PUBLISH_RATEBOOST — Unspecified
  [31] ENABLE, [7:0] EVENT
0xE54 PUBLISH_MHRMATCH — Unspecified
  [31] ENABLE, [7:0] EVENT
0xE58 PUBLISH_SYNC — Unspecified
  [31] ENABLE, [7:0] EVENT
0xE5C PUBLISH_CTEPRESENT — Unspecified
  [31] ENABLE, [7:0] EVENT
0xE60 PUBLISH_CTEWARNING — Unspecified
  [31] ENABLE, [7:0] EVENT
0xE64 PUBLISH_DFEEND — Unspecified
  [31] ENABLE, [7:0] EVENT
0xE68 PUBLISH_MODEWRITTEN — Unspecified
  [31] ENABLE, [7:0] EVENT
0xE6C PUBLISH_MODEREADY — Unspecified
  [31] ENABLE, [7:0] EVENT
0xE70 PUBLISH_CTEEND — Unspecified
  [31] ENABLE, [7:0] EVENT
0xE74 PUBLISH_LBREADY — Unspecified
  [31] ENABLE, [7:0] EVENT
0xE78 PUBLISH_CALDONE — Unspecified
  [31] ENABLE, [7:0] EVENT
0xE7C PUBLISH_CHNOUPDATED — Unspecified
  [31] ENABLE, [7:0] EVENT
0xE80 PUBLISH_DBCTIMEOUT — Unspecified
  [31] ENABLE, [7:0] EVENT
0xE84 PUBLISH_TXTIMERMATCH — Unspecified
  [31] ENABLE, [7:0] EVENT
0xE88 PUBLISH_RXTIMERMATCH — Unspecified
  [31] ENABLE, [7:0] EVENT
0xE8C PUBLISH_RESERVED35 — Unspecified
  [31] ENABLE, [7:0] EVENT
0xE90 PUBLISH_RXDIGEN — Unspecified
  [31] ENABLE, [7:0] EVENT
0xE94 PUBLISH_RAWDETECT — Unspecified
  [31] ENABLE, [7:0] EVENT
0xE98 PUBLISH_DETECTFIFOFULL — Unspecified
  [31] ENABLE, [7:0] EVENT
0xE9C PUBLISH_TIMERWRAPS — Unspecified
  [31] ENABLE, [7:0] EVENT
0xEA0 PUBLISH_STROBETIMETRACKUPDATED — Unspecified
  [31] ENABLE, [7:0] EVENT
{0xEA4+4i} PUBLISH_DEMODCTRLCONDTRIGGERED{i} (i=0..2) — Unspecified
  [31] ENABLE, [7:0] EVENT
{0xE00+4i} PUBLISH_RESERVED{i} (i=44..47) — Unspecified
  [31] ENABLE, [7:0] EVENT
0xEC0 PUBLISH_ACQINJ0DMAEND — Unspecified
  [31] ENABLE, [7:0] EVENT
0xEC4 PUBLISH_ACQINJ1DMAEND — Unspecified
  [31] ENABLE, [7:0] EVENT
0xF00 TASK_TRIG_ZERO_PENALTY_PCP_4 wo — Unspecified
  [0] TASK_TRIG_ZERO_PENALTY_PCP_4
0xF04 TASK_TRIG_FULL_PENALTY_PCP_4 wo — Unspecified
  [0] TASK_TRIG_FULL_PENALTY_PCP_4
0xF08 TASK_TRIG_ZERO_PENALTY_PCP_3 wo — Unspecified
  [0] TASK_TRIG_ZERO_PENALTY_PCP_3
0xF0C TASK_TRIG_FULL_PENALTY_PCP_3 wo — Unspecified
  [0] TASK_TRIG_FULL_PENALTY_PCP_3
0xF10 TASK_TRIG_ZERO_PENALTY_PCP_2 wo — Unspecified
  [0] TASK_TRIG_ZERO_PENALTY_PCP_2
0xF14 TASK_TRIG_FULL_PENALTY_PCP_2 wo — Unspecified
  [0] TASK_TRIG_FULL_PENALTY_PCP_2
0xF18 TASK_TRIG_ZERO_PENALTY_PCP_1 wo — Unspecified
  [0] TASK_TRIG_ZERO_PENALTY_PCP_1
0xF1C TASK_TRIG_FULL_PENALTY_PCP_1 wo — Unspecified
  [0] TASK_TRIG_FULL_PENALTY_PCP_1
0xF20 TASK_TRIG_ZERO_PENALTY_PCP_0 wo — Unspecified
  [0] TASK_TRIG_ZERO_PENALTY_PCP_0
0xF24 TASK_TRIG_FULL_PENALTY_PCP_0 wo — Unspecified
  [0] TASK_TRIG_FULL_PENALTY_PCP_0
0xF28 PENALTY_RG_PCP_0 — Unspecified
  [31:0] FIELD0
{0xF28+4i} PENALTY_RG_PCP_{i} reset 0xFFFFFFFC (i=1..4) — Unspecified
  [31:0] FIELD0
0xF3C TURN_OFF_AUTO_CLOCKSOURCE_REQ ro — Unspecified
  [4:0] FIELD0
{0xF40+4i} FORCE_OVERRIDE_PCP_{i} (i=0..4) — Unspecified
  [7] FIELD1, [1] FIELD0
